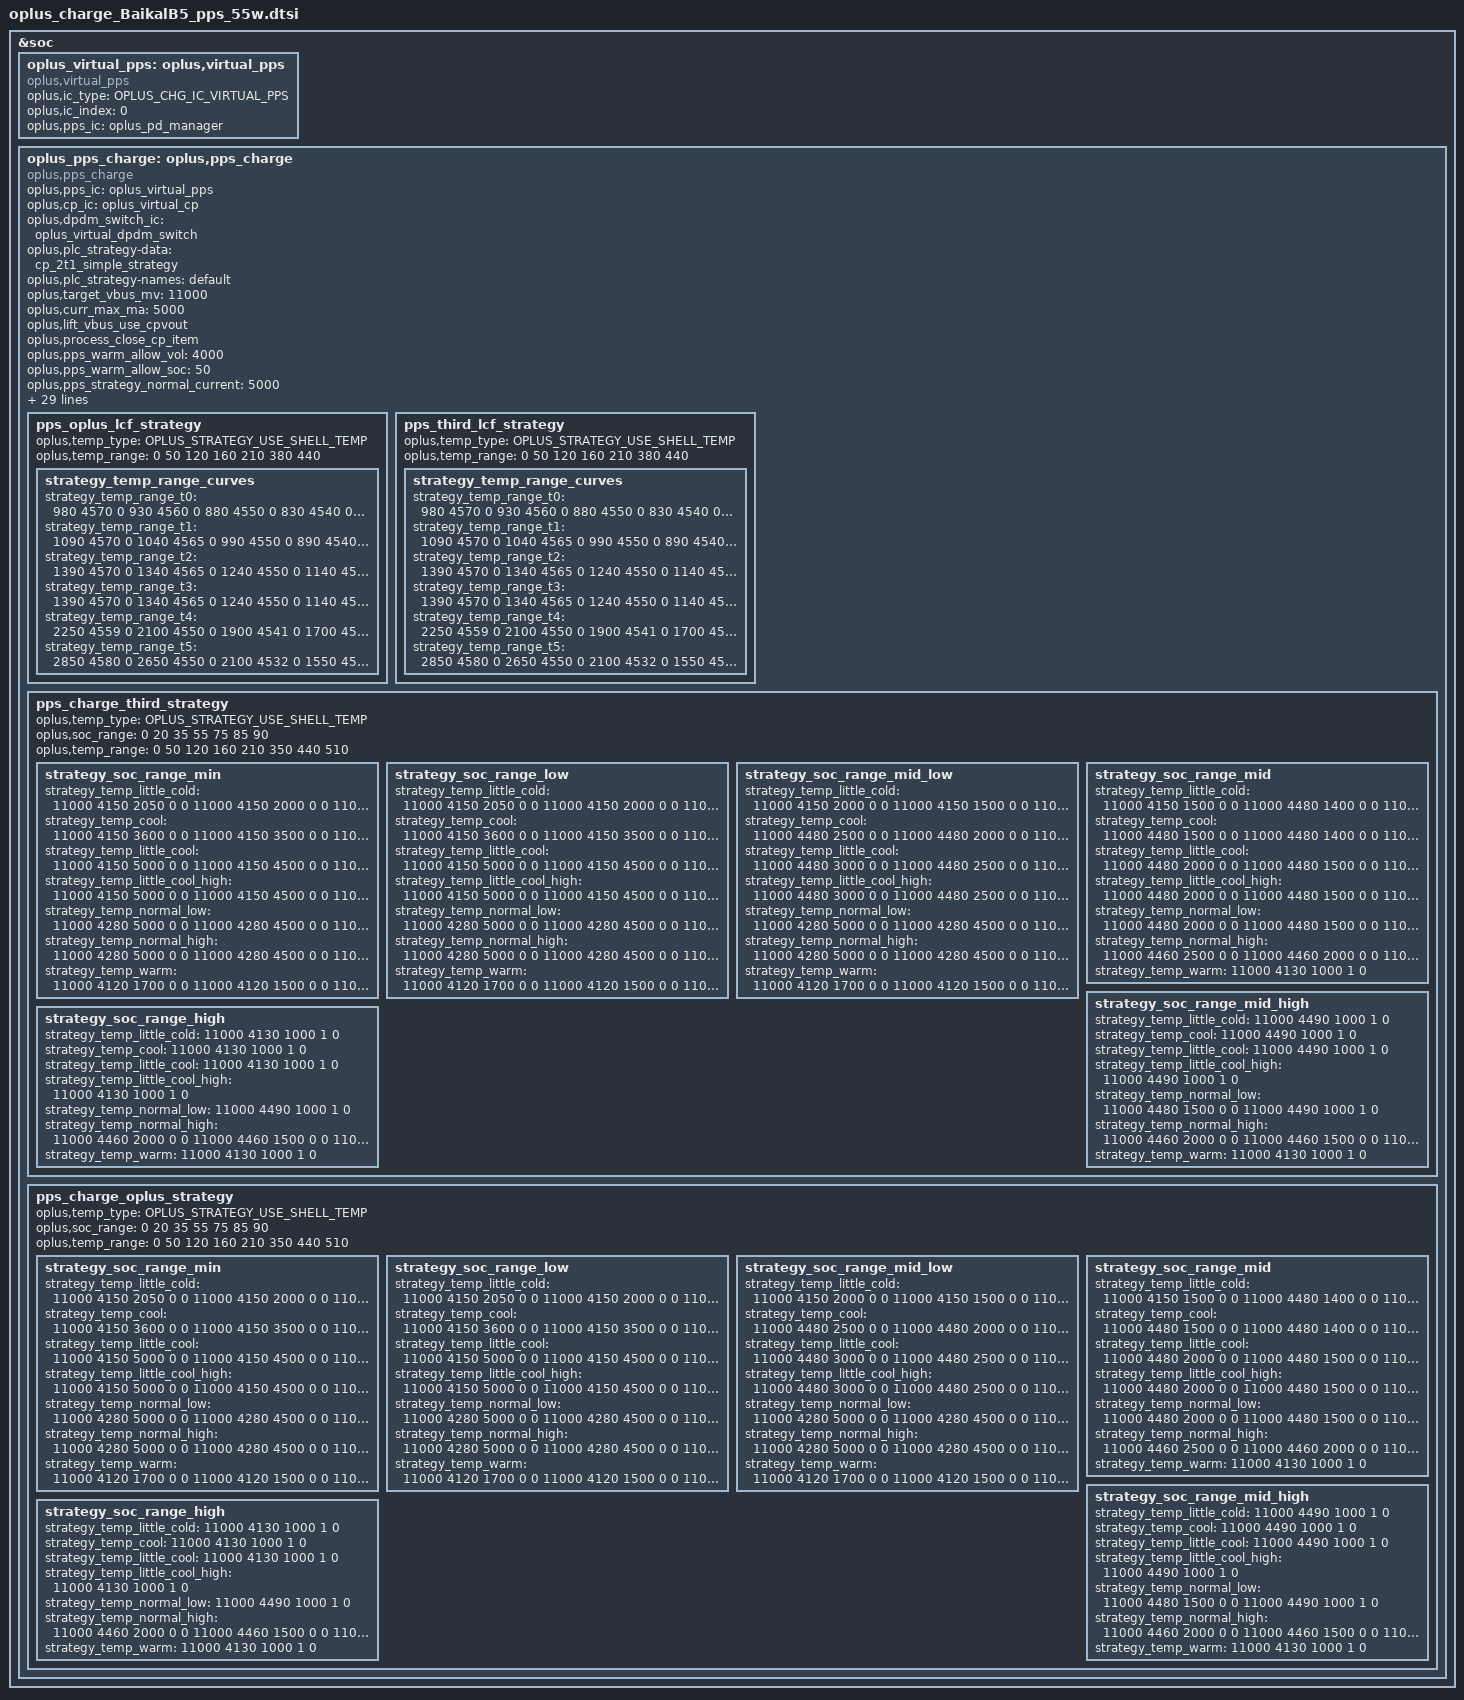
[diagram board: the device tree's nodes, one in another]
&soc {
	oplus_virtual_pps: oplus,virtual_pps {
		compatible = "oplus,virtual_pps";
		oplus,ic_type = <OPLUS_CHG_IC_VIRTUAL_PPS>;
		oplus,ic_index = <0>;
		oplus,pps_ic = <&oplus_pd_manager>;
	};

	oplus_pps_charge: oplus,pps_charge {
		compatible = "oplus,pps_charge";
		oplus,pps_ic = <&oplus_virtual_pps>;
		oplus,cp_ic = <&oplus_virtual_cp>;
		oplus,dpdm_switch_ic = <&oplus_virtual_dpdm_switch>;

		oplus,plc_strategy-data = <&cp_2t1_simple_strategy>;
		oplus,plc_strategy-names = "default";

		oplus,target_vbus_mv = <11000>;
		oplus,curr_max_ma = <5000>;

		oplus,lift_vbus_use_cpvout;
		oplus,process_close_cp_item;

		oplus,pps_warm_allow_vol = <4000>;
		oplus,pps_warm_allow_soc = <50>;
		oplus,pps_strategy_normal_current = <5000>;
		oplus,pps_over_high_or_low_current = <5000>;
		oplus,pps_timeout_third = <16225>;
		oplus,pps_timeout_oplus = <16225>;
		oplus,pps_ibat_over_third = <11400>;
		oplus,pps_ibat_over_oplus = <11400>;
		oplus,pps_full_cool_sw_vbat = <4490>;
		oplus,pps_full_normal_sw_vbat = <4550>;
		oplus,pps_full_normal_hw_vbat = <4560>;
		oplus,pps_full_ffc_vbat = <4500>;
		oplus,pps_full_warm_vbat = <4130>;
		oplus,pps_full_cool_sw_vbat_third = <4490>;
		oplus,pps_full_normal_sw_vbat_third= <4550>;
		oplus,pps_full_normal_hw_vbat_third = <4560>;
		oplus,pps_current_change_timeout = <100>;
		oplus,curve_strategy_name = "pps_ufcs_curve_v2";
		oplus,pps_r_default = <120 10 10 15 15 15 15>;
		oplus,pps_rmos_mohm = <4>;
		oplus,pps_r_limit = <280 200 140 90 50>;
		oplus,pps_strategy_batt_high_temp = <385 395 420 375 385 410>;
		oplus,pps_strategy_high_current = <3000 2000 2000 3000 3000 3000>;
		oplus,pps_charge_strategy_soc = <0 20 35 55 75 85 90>;
		oplus,pps_charge_strategy_temp = <0 50 120 160 350 440 510>;
		oplus,temperature_strategy_name = "cgcl";
		oplus,temperature_strategy_data = <OPLUS_STRATEGY_USE_SHELL_TEMP
						0   385 7300 1 0
						375 405 5000 2 0
						395 420 4000 3 1
						410 430 3500 4 2
						420 440 2000 4 3>;

		pps_oplus_lcf_strategy {
			oplus,temp_type = <OPLUS_STRATEGY_USE_SHELL_TEMP>;
			oplus,temp_range = <0 50 120 160 210 380 440>;

			strategy_temp_range_curves {
				strategy_temp_range_t0 =	<980 4570 0
								 930 4560 0
								 880 4550 0
								 830 4540 0
								 780 4530 1>;
				strategy_temp_range_t1 =	<1090 4570 0
								 1040 4565 0
								 990 4550 0
								 890 4540 0
								 790 4530 1>;
				strategy_temp_range_t2 =	<1390 4570 0
								 1340 4565 0
								 1240 4550 0
								 1140 4540 0
								 990 4530 1>;
				strategy_temp_range_t3 =	<1390 4570 0
								 1340 4565 0
								 1240 4550 0
								 1140 4540 0
								 990 4530 1>;
				strategy_temp_range_t4 =	<2250 4559 0
								 2100 4550 0
								 1900 4541 0
								 1700 4532 0
								 1500 4510 1>;
				strategy_temp_range_t5 =	<2850 4580 0
								 2650 4550 0
								 2100 4532 0
								 1550 4510 0
								 1000 4490 1>;
			};
		};

		pps_third_lcf_strategy {
			oplus,temp_type = <OPLUS_STRATEGY_USE_SHELL_TEMP>;
			oplus,temp_range = <0 50 120 160 210 380 440>;

			strategy_temp_range_curves {
				strategy_temp_range_t0 =	<980 4570 0
								 930 4560 0
								 880 4550 0
								 830 4540 0
								 780 4530 1>;
				strategy_temp_range_t1 =	<1090 4570 0
								 1040 4565 0
								 990 4550 0
								 890 4540 0
								 790 4530 1>;
				strategy_temp_range_t2 =	<1390 4570 0
								 1340 4565 0
								 1240 4550 0
								 1140 4540 0
								 990 4530 1>;
				strategy_temp_range_t3 =	<1390 4570 0
								 1340 4565 0
								 1240 4550 0
								 1140 4540 0
								 990 4530 1>;
				strategy_temp_range_t4 =	<2250 4559 0
								 2100 4550 0
								 1900 4541 0
								 1700 4532 0
								 1500 4510 1>;
				strategy_temp_range_t5 =	<2850 4580 0
								 2650 4550 0
								 2100 4532 0
								 1550 4510 0
								 1000 4490 1>;
			};
		};

		pps_charge_third_strategy {
			oplus,temp_type = <OPLUS_STRATEGY_USE_SHELL_TEMP>;
			oplus,soc_range = <0 20 35 55 75 85 90>;
			oplus,temp_range = <0 50 120 160 210 350 440 510>;

			strategy_soc_range_min {
				strategy_temp_little_cold =	<11000 4150 2050 0 0
								11000 4150 2000 0 0
								11000 4150 1500 0 0
								11000 4480 1400 0 0
								11000 4490 1000 1 0>;
				strategy_temp_cool =		<11000 4150 3600 0 0
								11000 4150 3500 0 0
								11000 4150 3000 0 0
								11000 4480 2700 0 0
								11000 4480 2500 0 0
								11000 4480 2000 0 0
								11000 4480 1500 0 0
								11000 4480 1400 0 0
								11000 4490 1000 1 0>;
				strategy_temp_little_cool =	<11000 4150 5000 0 0
								11000 4150 4500 0 0
								11000 4150 4000 0 0
								11000 4480 3900 0 0
								11000 4480 3500 0 0
								11000 4480 3000 0 0
								11000 4480 2500 0 0
								11000 4480 2000 0 0
								11000 4480 1500 0 0
								11000 4490 1000 1 0>;
				strategy_temp_little_cool_high =<11000 4150 5000 0 0
								11000 4150 4500 0 0
								11000 4150 4000 0 0
								11000 4480 3900 0 0
								11000 4480 3500 0 0
								11000 4480 3000 0 0
								11000 4480 2500 0 0
								11000 4480 2000 0 0
								11000 4480 1500 0 0
								11000 4490 1000 1 0>;
				strategy_temp_normal_low =	<11000 4280 5000 0 0
								11000 4280 4500 0 0
								11000 4480 4200 0 0
								11000 4480 4000 0 0
								11000 4480 3500 0 0
								11000 4480 3300 0 0
								11000 4480 3000 0 0
								11000 4480 2500 0 0
								11000 4480 2000 0 0
								11000 4480 1500 0 0
								11000 4490 1000 1 0>;
				strategy_temp_normal_high =	<11000 4280 5000 0 0
								11000 4280 4500 0 0
								11000 4460 4200 0 0
								11000 4460 4000 0 0
								11000 4460 3500 0 0
								11000 4460 3300 0 0
								11000 4460 3000 0 0
								11000 4460 2500 0 0
								11000 4460 2000 0 0
								11000 4460 1500 0 0
								11000 4470 1000 1 0>;
				strategy_temp_warm =		<11000 4120 1700 0 0
								11000 4120 1500 0 0
								11000 4130 1000 1 0>;
			};
			strategy_soc_range_low {
				strategy_temp_little_cold =	<11000 4150 2050 0 0
								11000 4150 2000 0 0
								11000 4150 1500 0 0
								11000 4480 1400 0 0
								11000 4490 1000 1 0>;
				strategy_temp_cool =		<11000 4150 3600 0 0
								11000 4150 3500 0 0
								11000 4150 3000 0 0
								11000 4480 2700 0 0
								11000 4480 2500 0 0
								11000 4480 2000 0 0
								11000 4480 1500 0 0
								11000 4480 1400 0 0
								11000 4490 1000 1 0>;
				strategy_temp_little_cool =	<11000 4150 5000 0 0
								11000 4150 4500 0 0
								11000 4150 4000 0 0
								11000 4480 3900 0 0
								11000 4480 3500 0 0
								11000 4480 3000 0 0
								11000 4480 2500 0 0
								11000 4480 2000 0 0
								11000 4480 1500 0 0
								11000 4490 1000 1 0>;
				strategy_temp_little_cool_high =<11000 4150 5000 0 0
								11000 4150 4500 0 0
								11000 4150 4000 0 0
								11000 4480 3900 0 0
								11000 4480 3500 0 0
								11000 4480 3000 0 0
								11000 4480 2500 0 0
								11000 4480 2000 0 0
								11000 4480 1500 0 0
								11000 4490 1000 1 0>;
				strategy_temp_normal_low =	<11000 4280 5000 0 0
								11000 4280 4500 0 0
								11000 4480 4200 0 0
								11000 4480 4000 0 0
								11000 4480 3500 0 0
								11000 4480 3300 0 0
								11000 4480 3000 0 0
								11000 4480 2500 0 0
								11000 4480 2000 0 0
								11000 4480 1500 0 0
								11000 4490 1000 1 0>;
				strategy_temp_normal_high =	<11000 4280 5000 0 0
								11000 4280 4500 0 0
								11000 4460 4200 0 0
								11000 4460 4000 0 0
								11000 4460 3500 0 0
								11000 4460 3300 0 0
								11000 4460 3000 0 0
								11000 4460 2500 0 0
								11000 4460 2000 0 0
								11000 4460 1500 0 0
								11000 4470 1000 1 0>;
				strategy_temp_warm =		<11000 4120 1700 0 0
								11000 4120 1500 0 0
								11000 4130 1000 1 0>;
			};
			strategy_soc_range_mid_low {
				strategy_temp_little_cold =	<11000 4150 2000 0 0
								11000 4150 1500 0 0
								11000 4480 1400 0 0
								11000 4490 1000 1 0>;
				strategy_temp_cool =		<11000 4480 2500 0 0
								11000 4480 2000 0 0
								11000 4480 1500 0 0
								11000 4480 1400 0 0
								11000 4490 1000 1 0>;
				strategy_temp_little_cool =	<11000 4480 3000 0 0
								11000 4480 2500 0 0
								11000 4480 2000 0 0
								11000 4480 1500 0 0
								11000 4490 1000 1 0>;
				strategy_temp_little_cool_high =<11000 4480 3000 0 0
								11000 4480 2500 0 0
								11000 4480 2000 0 0
								11000 4480 1500 0 0
								11000 4490 1000 1 0>;
				strategy_temp_normal_low =	<11000 4280 5000 0 0
								11000 4280 4500 0 0
								11000 4480 4200 0 0
								11000 4480 4000 0 0
								11000 4480 3500 0 0
								11000 4480 3300 0 0
								11000 4480 3000 0 0
								11000 4480 2500 0 0
								11000 4480 2000 0 0
								11000 4480 1500 0 0
								11000 4490 1000 1 0>;
				strategy_temp_normal_high =	<11000 4280 5000 0 0
								11000 4280 4500 0 0
								11000 4460 4200 0 0
								11000 4460 4000 0 0
								11000 4460 3500 0 0
								11000 4460 3300 0 0
								11000 4460 3000 0 0
								11000 4460 2500 0 0
								11000 4460 2000 0 0
								11000 4460 1500 0 0
								11000 4470 1000 1 0>;
				strategy_temp_warm =		<11000 4120 1700 0 0
								11000 4120 1500 0 0
								11000 4130 1000 1 0>;
			};
			strategy_soc_range_mid {
				strategy_temp_little_cold =	<11000 4150 1500 0 0
								11000 4480 1400 0 0
								11000 4490 1000 1 0>;
				strategy_temp_cool =		<11000 4480 1500 0 0
								11000 4480 1400 0 0
								11000 4490 1000 1 0>;
				strategy_temp_little_cool =	<11000 4480 2000 0 0
								11000 4480 1500 0 0
								11000 4490 1000 1 0>;
				strategy_temp_little_cool_high =<11000 4480 2000 0 0
								11000 4480 1500 0 0
								11000 4490 1000 1 0>;
				strategy_temp_normal_low =	<11000 4480 2000 0 0
								11000 4480 1500 0 0
								11000 4490 1000 1 0>;
				strategy_temp_normal_high =	<11000 4460 2500 0 0
								11000 4460 2000 0 0
								11000 4460 1500 0 0
								11000 4470 1000 1 0>;
				strategy_temp_warm =		<11000 4130 1000 1 0>;
			};
			strategy_soc_range_mid_high {
				strategy_temp_little_cold =	<11000 4490 1000 1 0>;
				strategy_temp_cool =		<11000 4490 1000 1 0>;
				strategy_temp_little_cool =	<11000 4490 1000 1 0>;
				strategy_temp_little_cool_high =<11000 4490 1000 1 0>;
				strategy_temp_normal_low =	<11000 4480 1500 0 0
								11000 4490 1000 1 0>;
				strategy_temp_normal_high =	<11000 4460 2000 0 0
								11000 4460 1500 0 0
								11000 4470 1000 1 0>;
				strategy_temp_warm =		<11000 4130 1000 1 0>;
			};
			strategy_soc_range_high {
				strategy_temp_little_cold =	<11000 4130 1000 1 0>;
				strategy_temp_cool =		<11000 4130 1000 1 0>;
				strategy_temp_little_cool =	<11000 4130 1000 1 0>;
				strategy_temp_little_cool_high =<11000 4130 1000 1 0>;
				strategy_temp_normal_low =	<11000 4490 1000 1 0>;
				strategy_temp_normal_high =	<11000 4460 2000 0 0
								11000 4460 1500 0 0
								11000 4470 1000 1 0>;
				strategy_temp_warm =		<11000 4130 1000 1 0>;
			};
		};

		pps_charge_oplus_strategy {
			oplus,temp_type = <OPLUS_STRATEGY_USE_SHELL_TEMP>;
			oplus,soc_range = <0 20 35 55 75 85 90>;
			oplus,temp_range = <0 50 120 160 210 350 440 510>;

			strategy_soc_range_min {
				strategy_temp_little_cold =	<11000 4150 2050 0 0
								11000 4150 2000 0 0
								11000 4150 1500 0 0
								11000 4480 1400 0 0
								11000 4490 1000 1 0>;
				strategy_temp_cool =		<11000 4150 3600 0 0
								11000 4150 3500 0 0
								11000 4150 3000 0 0
								11000 4480 2700 0 0
								11000 4480 2500 0 0
								11000 4480 2000 0 0
								11000 4480 1500 0 0
								11000 4480 1400 0 0
								11000 4490 1000 1 0>;
				strategy_temp_little_cool =	<11000 4150 5000 0 0
								11000 4150 4500 0 0
								11000 4150 4000 0 0
								11000 4480 3900 0 0
								11000 4480 3500 0 0
								11000 4480 3000 0 0
								11000 4480 2500 0 0
								11000 4480 2000 0 0
								11000 4480 1500 0 0
								11000 4490 1000 1 0>;
				strategy_temp_little_cool_high =<11000 4150 5000 0 0
								11000 4150 4500 0 0
								11000 4150 4000 0 0
								11000 4480 3900 0 0
								11000 4480 3500 0 0
								11000 4480 3000 0 0
								11000 4480 2500 0 0
								11000 4480 2000 0 0
								11000 4480 1500 0 0
								11000 4490 1000 1 0>;
				strategy_temp_normal_low =	<11000 4280 5000 0 0
								11000 4280 4500 0 0
								11000 4480 4200 0 0
								11000 4480 4000 0 0
								11000 4480 3500 0 0
								11000 4480 3300 0 0
								11000 4480 3000 0 0
								11000 4480 2500 0 0
								11000 4480 2000 0 0
								11000 4480 1500 0 0
								11000 4490 1000 1 0>;
				strategy_temp_normal_high =	<11000 4280 5000 0 0
								11000 4280 4500 0 0
								11000 4460 4200 0 0
								11000 4460 4000 0 0
								11000 4460 3500 0 0
								11000 4460 3300 0 0
								11000 4460 3000 0 0
								11000 4460 2500 0 0
								11000 4460 2000 0 0
								11000 4460 1500 0 0
								11000 4470 1000 1 0>;
				strategy_temp_warm =		<11000 4120 1700 0 0
								11000 4120 1500 0 0
								11000 4130 1000 1 0>;
			};
			strategy_soc_range_low {
				strategy_temp_little_cold =	<11000 4150 2050 0 0
								11000 4150 2000 0 0
								11000 4150 1500 0 0
								11000 4480 1400 0 0
								11000 4490 1000 1 0>;
				strategy_temp_cool =		<11000 4150 3600 0 0
								11000 4150 3500 0 0
								11000 4150 3000 0 0
								11000 4480 2700 0 0
								11000 4480 2500 0 0
								11000 4480 2000 0 0
								11000 4480 1500 0 0
								11000 4480 1400 0 0
								11000 4490 1000 1 0>;
				strategy_temp_little_cool =	<11000 4150 5000 0 0
								11000 4150 4500 0 0
								11000 4150 4000 0 0
								11000 4480 3900 0 0
								11000 4480 3500 0 0
								11000 4480 3000 0 0
								11000 4480 2500 0 0
								11000 4480 2000 0 0
								11000 4480 1500 0 0
								11000 4490 1000 1 0>;
				strategy_temp_little_cool_high =<11000 4150 5000 0 0
								11000 4150 4500 0 0
								11000 4150 4000 0 0
								11000 4480 3900 0 0
								11000 4480 3500 0 0
								11000 4480 3000 0 0
								11000 4480 2500 0 0
								11000 4480 2000 0 0
								11000 4480 1500 0 0
								11000 4490 1000 1 0>;
				strategy_temp_normal_low =	<11000 4280 5000 0 0
								11000 4280 4500 0 0
								11000 4480 4200 0 0
								11000 4480 4000 0 0
								11000 4480 3500 0 0
								11000 4480 3300 0 0
								11000 4480 3000 0 0
								11000 4480 2500 0 0
								11000 4480 2000 0 0
								11000 4480 1500 0 0
								11000 4490 1000 1 0>;
				strategy_temp_normal_high =	<11000 4280 5000 0 0
								11000 4280 4500 0 0
								11000 4460 4200 0 0
								11000 4460 4000 0 0
								11000 4460 3500 0 0
								11000 4460 3300 0 0
								11000 4460 3000 0 0
								11000 4460 2500 0 0
								11000 4460 2000 0 0
								11000 4460 1500 0 0
								11000 4470 1000 1 0>;
				strategy_temp_warm =		<11000 4120 1700 0 0
								11000 4120 1500 0 0
								11000 4130 1000 1 0>;
			};
			strategy_soc_range_mid_low {
				strategy_temp_little_cold =	<11000 4150 2000 0 0
								11000 4150 1500 0 0
								11000 4480 1400 0 0
								11000 4490 1000 1 0>;
				strategy_temp_cool =		<11000 4480 2500 0 0
								11000 4480 2000 0 0
								11000 4480 1500 0 0
								11000 4480 1400 0 0
								11000 4490 1000 1 0>;
				strategy_temp_little_cool =	<11000 4480 3000 0 0
								11000 4480 2500 0 0
								11000 4480 2000 0 0
								11000 4480 1500 0 0
								11000 4490 1000 1 0>;
				strategy_temp_little_cool_high =<11000 4480 3000 0 0
								11000 4480 2500 0 0
								11000 4480 2000 0 0
								11000 4480 1500 0 0
								11000 4490 1000 1 0>;
				strategy_temp_normal_low =	<11000 4280 5000 0 0
								11000 4280 4500 0 0
								11000 4480 4200 0 0
								11000 4480 4000 0 0
								11000 4480 3500 0 0
								11000 4480 3300 0 0
								11000 4480 3000 0 0
								11000 4480 2500 0 0
								11000 4480 2000 0 0
								11000 4480 1500 0 0
								11000 4490 1000 1 0>;
				strategy_temp_normal_high =	<11000 4280 5000 0 0
								11000 4280 4500 0 0
								11000 4460 4200 0 0
								11000 4460 4000 0 0
								11000 4460 3500 0 0
								11000 4460 3300 0 0
								11000 4460 3000 0 0
								11000 4460 2500 0 0
								11000 4460 2000 0 0
								11000 4460 1500 0 0
								11000 4470 1000 1 0>;
				strategy_temp_warm =		<11000 4120 1700 0 0
								11000 4120 1500 0 0
								11000 4130 1000 1 0>;
			};
			strategy_soc_range_mid {
				strategy_temp_little_cold =	<11000 4150 1500 0 0
								11000 4480 1400 0 0
								11000 4490 1000 1 0>;
				strategy_temp_cool =		<11000 4480 1500 0 0
								11000 4480 1400 0 0
								11000 4490 1000 1 0>;
				strategy_temp_little_cool =	<11000 4480 2000 0 0
								11000 4480 1500 0 0
								11000 4490 1000 1 0>;
				strategy_temp_little_cool_high =<11000 4480 2000 0 0
								11000 4480 1500 0 0
								11000 4490 1000 1 0>;
				strategy_temp_normal_low =	<11000 4480 2000 0 0
								11000 4480 1500 0 0
								11000 4490 1000 1 0>;
				strategy_temp_normal_high =	<11000 4460 2500 0 0
								11000 4460 2000 0 0
								11000 4460 1500 0 0
								11000 4470 1000 1 0>;
				strategy_temp_warm =		<11000 4130 1000 1 0>;
			};
			strategy_soc_range_mid_high {
				strategy_temp_little_cold =	<11000 4490 1000 1 0>;
				strategy_temp_cool =		<11000 4490 1000 1 0>;
				strategy_temp_little_cool =	<11000 4490 1000 1 0>;
				strategy_temp_little_cool_high =<11000 4490 1000 1 0>;
				strategy_temp_normal_low =	<11000 4480 1500 0 0
								11000 4490 1000 1 0>;
				strategy_temp_normal_high =	<11000 4460 2000 0 0
								11000 4460 1500 0 0
								11000 4470 1000 1 0>;
				strategy_temp_warm =		<11000 4130 1000 1 0>;
			};
			strategy_soc_range_high {
				strategy_temp_little_cold =	<11000 4130 1000 1 0>;
				strategy_temp_cool =		<11000 4130 1000 1 0>;
				strategy_temp_little_cool =	<11000 4130 1000 1 0>;
				strategy_temp_little_cool_high =<11000 4130 1000 1 0>;
				strategy_temp_normal_low =	<11000 4490 1000 1 0>;
				strategy_temp_normal_high =	<11000 4460 2000 0 0
								11000 4460 1500 0 0
								11000 4470 1000 1 0>;
				strategy_temp_warm =		<11000 4130 1000 1 0>;
			};
		};
	};
};
